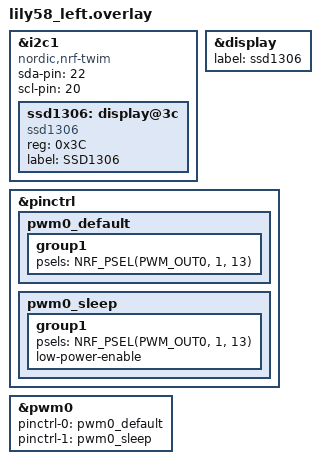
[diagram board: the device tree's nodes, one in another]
&i2c1 {
    compatible = "nordic,nrf-twim";
    status = "okay";
    sda-pin = <22>; // Update with your SDA pin
    scl-pin = <20>; // Update with your SCL pin

    ssd1306: display@3c {
        compatible = "ssd1306";
        reg = <0x3C>; // I2C address of your display
        label = "SSD1306";
    };
};

&display {
    status = "okay";
    label = "ssd1306";
};

&pinctrl {
    // Other pinctrl definitions for other hardware
    pwm0_default: pwm0_default {
        group1 {
            psels = <NRF_PSEL(PWM_OUT0, 1, 13)>;
        };
    };
    pwm0_sleep: pwm0_sleep {
        group1 {
            psels = <NRF_PSEL(PWM_OUT0, 1, 13)>;
            low-power-enable;
        };
    };
};

&pwm0 {
    status = "okay";
    pinctrl-0 = <&pwm0_default>;
    pinctrl-1 = <&pwm0_sleep>;
    pinctrl-names = "default", "sleep";
};
